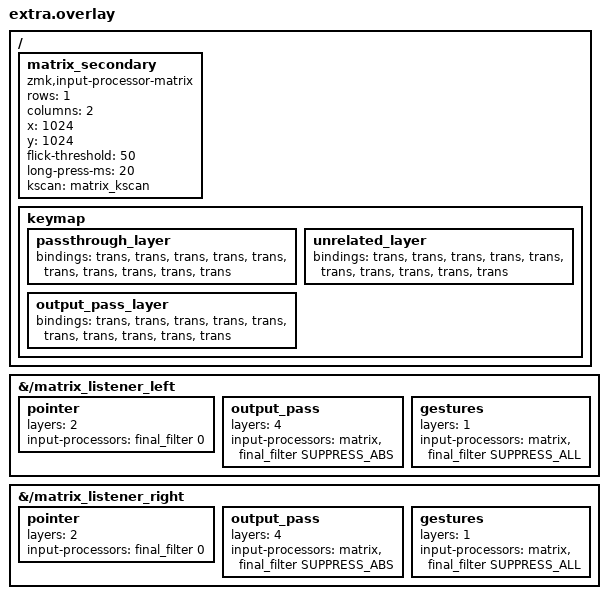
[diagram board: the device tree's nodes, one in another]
/* SPDX-License-Identifier: MIT */
/ {
    matrix_secondary: matrix_secondary {
        compatible = "zmk,input-processor-matrix";
        #input-processor-cells = <0>;
        rows = <1>;
        columns = <2>;
        x = <1024>;
        y = <1024>;
        flick-threshold = <50>;
        long-press-ms = <20>;

        kscan = <&matrix_kscan>;
    };
};

/ {
    keymap {
        passthrough_layer { bindings = <&trans &trans &trans &trans &trans
                                       &trans &trans &trans &trans &trans>; };
        unrelated_layer { bindings = <&trans &trans &trans &trans &trans
                                     &trans &trans &trans &trans &trans>; };
        output_pass_layer { bindings = <&trans &trans &trans &trans &trans
                                       &trans &trans &trans &trans &trans>; };
    };
};
&{/matrix_listener_left} {
    pointer { layers = <2>; input-processors = <&final_filter 0>; };
    output_pass { layers = <4>; input-processors = <&matrix>, <&final_filter SUPPRESS_ABS>; };
    gestures { layers = <1>; input-processors = <&matrix>, <&final_filter SUPPRESS_ALL>; };
};
&{/matrix_listener_right} {
    pointer { layers = <2>; input-processors = <&final_filter 0>; };
    output_pass { layers = <4>; input-processors = <&matrix>, <&final_filter SUPPRESS_ABS>; };
    gestures { layers = <1>; input-processors = <&matrix>, <&final_filter SUPPRESS_ALL>; };
};
